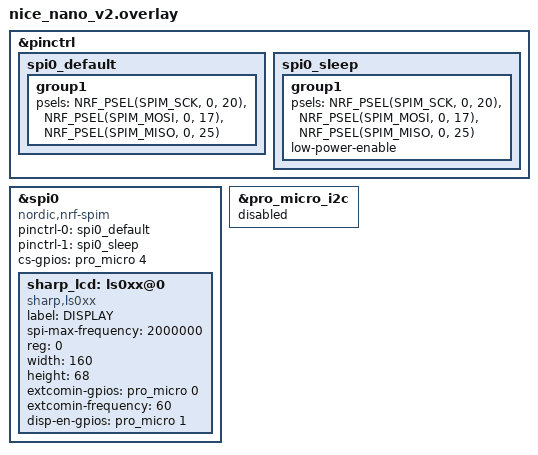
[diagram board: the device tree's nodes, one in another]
/*
 * Copyright (c) 2021 The ZMK Contributors
 *
 * SPDX-License-Identifier: MIT
 */

 &pinctrl {
    spi0_default: spi0_default {
        group1 {
            psels = <NRF_PSEL(SPIM_SCK, 0, 20)>,
                <NRF_PSEL(SPIM_MOSI, 0, 17)>,
                <NRF_PSEL(SPIM_MISO, 0, 25)>;
        };
    };
    spi0_sleep: spi0_sleep {
        group1 {
            psels = <NRF_PSEL(SPIM_SCK, 0, 20)>,
                <NRF_PSEL(SPIM_MOSI, 0, 17)>,
                <NRF_PSEL(SPIM_MISO, 0, 25)>;
            low-power-enable;
        };
    };
};

&spi0 {
    status = "okay";
    compatible = "nordic,nrf-spim";
    pinctrl-0 = <&spi0_default>;
    pinctrl-1 = <&spi0_sleep>;
    pinctrl-names = "default", "sleep";
    cs-gpios = <&pro_micro 4 GPIO_ACTIVE_HIGH>;

	sharp_lcd: ls0xx@0 {
		compatible = "sharp,ls0xx";
		label = "DISPLAY";
		spi-max-frequency = <2000000>;
		reg = <0>;
		width = <160>;
		height = <68>;
		extcomin-gpios = <&pro_micro 0 GPIO_ACTIVE_HIGH>;
		extcomin-frequency = <60>;
		disp-en-gpios = <&pro_micro 1 GPIO_ACTIVE_HIGH>; 
	};
};

&pro_micro_i2c {
    status = "disabled";
};
